VERSION ""

NS_ :

BS_:

BU_: BMS

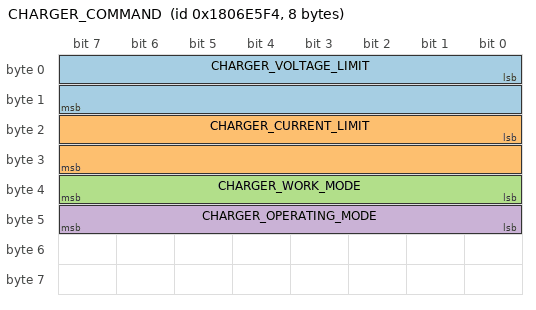
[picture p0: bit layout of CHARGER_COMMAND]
BO_ 403105268 CHARGER_COMMAND: 8 Vector__XXX
 SG_ CHARGER_VOLTAGE_LIMIT : 0|16@1+ (0.1,0) [0|680] "V" Vector__XXX
 SG_ CHARGER_CURRENT_LIMIT : 16|16@1+ (0.1,0) [0|14] "A" Vector__XXX
 SG_ CHARGER_WORK_MODE : 32|8@1+ (1,0) [0|2] "Enum" Vector__XXX
 SG_ CHARGER_OPERATING_MODE : 40|8@1+ (1,0) [0|0] "Enum" Vector__XXX

BO_ 419385573 CHARGER_RESPONSE: 8 Vector__XXX
 SG_ CHARGE_VOLTGE_OUTPUT : 0|16@1+ (0.1,0) [0|680] "V" Vector__XXX
 SG_ CHARGER_CURRENT_OUTPUT : 16|16@1+ (0.1,0) [0|14] "A" Vector__XXX
 SG_ CHARGER_HARDWARE_PROTECTION : 32|1@1+ (1,0) [0|1] "Bool" Vector__XXX
 SG_ CHARGER_TEMPERATURE_PROTECTION : 33|1@1+ (1,0) [0|1] "Bool" Vector__XXX
 SG_ CHARGER_INPUT_VOLTAGE_STATUS : 34|2@1+ (1,0) [0|1] "Bool" Vector__XXX
 SG_ CHARGER_OUTPUT_UNDERVOLTAGE : 36|1@1+ (1,0) [0|1] "Bool" Vector__XXX
 SG_ CHARGER_OUTPUT_OVERVOLTAGE : 37|1@1+ (1,0) [0|1] "Bool" Vector__XXX
 SG_ CHARGE__OUTPUT_OVERCURRENT : 38|1@1+ (1,0) [0|1] "Bool" Vector__XXX
 SG_ CHARGER_OUTPUT_SHORT_CIRCUIT : 39|1@1+ (1,0) [0|1] "Bool" Vector__XXX
 SG_ CHARGER_COMMAND_FAULT : 40|1@1+ (1,0) [0|1] "Bool" Vector__XXX
 SG_ CHARGER_WORK_STATUS : 41|2@1+ (1,0) [0|3] "Enum" Vector__XXX
 SG_ CHARGER_INITIALIZED : 43|1@1+ (1,0) [0|1] "Bool" Vector__XXX
 SG_ CHARGER_FAN_ENABLED : 44|1@1+ (1,0) [0|1] "Bool" Vector__XXX
 SG_ CHARGER_COOLING_PUMP_ENABLED : 45|1@1+ (1,0) [0|1] "Bool" Vector__XXX
 SG_ CHARGER_CC_STATUS : 48|2@1+ (1,0) [0|3] "Enum" Vector__XXX
 SG_ CHARGER_CP_STATUS : 50|1@1+ (1,0) [0|1] "Bool" Vector__XXX
 SG_ CHARGER_SOCKET_OVERTEMPERATURE : 51|1@1+ (1,0) [0|1] "Bool" Vector__XXX
 SG_ CHARGER_ELECTRONIC_LOCK : 52|3@1+ (1,0) [0|4] "Enum" Vector__XXX
 SG_ CHARGER_S2_SWITCH_CONTROL : 55|1@1+ (1,0) [0|1] "Bool" Vector__XXX
 SG_ CHARGER_TEMPERATURE : 56|8@1+ (1,-40) [-40|205] "C" Vector__XXX

BA_DEF_  "BusType" STRING ;
BA_DEF_DEF_  "BusType" "CAN";

CM_ SG_ 1012 CHARGER_OPERATING_MODE "Must be 0.";
